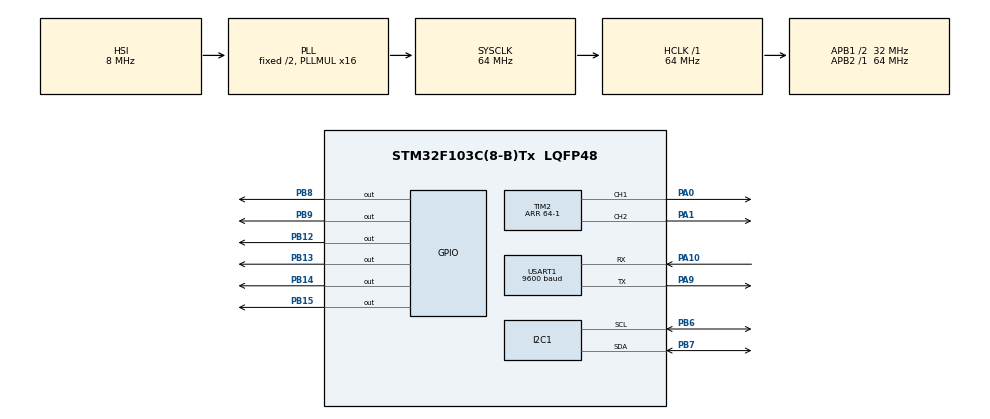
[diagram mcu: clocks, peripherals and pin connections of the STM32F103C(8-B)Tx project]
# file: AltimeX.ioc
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Dma.Request0=TIM2_CH2/CH4
Dma.Request1=USART1_RX
Dma.TIM2_CH2/CH4.0.Direction=DMA_MEMORY_TO_PERIPH
Dma.TIM2_CH2/CH4.0.Instance=DMA1_Channel7
Dma.TIM2_CH2/CH4.0.MemDataAlignment=DMA_MDATAALIGN_HALFWORD
Dma.TIM2_CH2/CH4.0.MemInc=DMA_MINC_ENABLE
Dma.TIM2_CH2/CH4.0.Mode=DMA_NORMAL
Dma.TIM2_CH2/CH4.0.PeriphDataAlignment=DMA_PDATAALIGN_HALFWORD
Dma.TIM2_CH2/CH4.0.PeriphInc=DMA_PINC_DISABLE
Dma.TIM2_CH2/CH4.0.Priority=DMA_PRIORITY_LOW
Dma.USART1_RX.1.Direction=DMA_PERIPH_TO_MEMORY
Dma.USART1_RX.1.Instance=DMA1_Channel5
Dma.USART1_RX.1.MemDataAlignment=DMA_MDATAALIGN_BYTE
Dma.USART1_RX.1.MemInc=DMA_MINC_ENABLE
Dma.USART1_RX.1.Mode=DMA_CIRCULAR
Dma.USART1_RX.1.PeriphDataAlignment=DMA_PDATAALIGN_BYTE
Dma.USART1_RX.1.PeriphInc=DMA_PINC_DISABLE
Dma.USART1_RX.1.Priority=DMA_PRIORITY_LOW
I2C1.I2C_Mode=I2C_Standard
Mcu.Family=STM32F1
Mcu.Name=STM32F103C(8-B)Tx
Mcu.Package=LQFP48
NVIC.DMA1_Channel5_IRQn=true\:0\:0\:false\:false\:true\:false\:true\:true
NVIC.DMA1_Channel7_IRQn=true\:0\:0\:false\:false\:true\:false\:true\:true
NVIC.PriorityGroup=NVIC_PRIORITYGROUP_4
NVIC.USART1_IRQn=true\:0\:0\:false\:false\:true\:true\:true\:true
PA0-WKUP.Signal=S_TIM2_CH1_ETR
PA1.Signal=S_TIM2_CH2
PA10.Mode=Asynchronous
PA10.Signal=USART1_RX
PA9.Mode=Asynchronous
PA9.Signal=USART1_TX
PB12.Signal=GPIO_Output
PB13.Signal=GPIO_Output
PB14.Signal=GPIO_Output
PB15.Signal=GPIO_Output
PB6.Mode=I2C
PB6.Signal=I2C1_SCL
PB7.Mode=I2C
PB7.Signal=I2C1_SDA
PB8.Signal=GPIO_Output
PB9.Signal=GPIO_Output
ProjectManager.HeapSize=0x200
ProjectManager.StackSize=0x400
ProjectManager.TargetToolchain=STM32CubeIDE
RCC.ADCPresc=RCC_ADCPCLK2_DIV6
RCC.AHBFreq_Value=64000000
RCC.APB1CLKDivider=RCC_HCLK_DIV2
RCC.APB1Freq_Value=32000000
RCC.APB1TimFreq_Value=64000000
RCC.APB2Freq_Value=64000000
RCC.APB2TimFreq_Value=64000000
RCC.HCLKFreq_Value=64000000
RCC.PLLMUL=RCC_PLL_MUL16
RCC.SYSCLKFreq_VALUE=64000000
RCC.SYSCLKSource=RCC_SYSCLKSOURCE_PLLCLK
RCC.USBFreq_Value=64000000
SH.S_TIM2_CH1_ETR.0=TIM2_CH1,PWM Generation1 CH1
SH.S_TIM2_CH2.0=TIM2_CH2,PWM Generation2 CH2
TIM1.Prescaler=4-1
TIM2.Channel-PWM\ Generation1\ CH1=TIM_CHANNEL_1
TIM2.Channel-PWM\ Generation2\ CH2=TIM_CHANNEL_2
TIM2.Period=64-1
USART1.BaudRate=9600
USART1.VirtualMode=VM_ASYNC
VP_TIM1_VS_ClockSourceINT.Mode=Internal
VP_TIM2_VS_ClockSourceINT.Mode=Internal
board=custom

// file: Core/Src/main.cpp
/* USER CODE BEGIN Header */
/**
  ******************************************************************************
  * @file           : main.c
  * @brief          : Main program body
  ******************************************************************************
  * @attention
  *
  * Copyright (c) 2023 STMicroelectronics.
  * All rights reserved.
  *
  * This software is licensed under terms that can be found in the LICENSE file
  * in the root directory of this software component.
  * If no LICENSE file comes with this software, it is provided AS-IS.
  *
  ******************************************************************************
  */
/* USER CODE END Header */
#include "main.h"

/* USER CODE BEGIN Includes */
#include "altimex.h"
/* USER CODE END Includes */

I2C_HandleTypeDef hi2c1;

TIM_HandleTypeDef htim1;
TIM_HandleTypeDef htim2;
DMA_HandleTypeDef hdma_tim2_ch2_ch4;

UART_HandleTypeDef huart1;
DMA_HandleTypeDef hdma_usart1_rx;

void SystemClock_Config(void);
static void MX_GPIO_Init(void);
static void MX_DMA_Init(void);
static void MX_I2C1_Init(void);
static void MX_TIM2_Init(void);
static void MX_TIM1_Init(void);
static void MX_USART1_UART_Init(void);

int main(void)
{

  /* MCU Configuration--------------------------------------------------------*/

  /* Reset of all peripherals, Initializes the Flash interface and the Systick. */
  HAL_Init();

  /* Configure the system clock */
  SystemClock_Config();

  /* Initialize all configured peripherals */
  MX_GPIO_Init();
  MX_DMA_Init();
  MX_I2C1_Init();
  MX_TIM2_Init();
  MX_TIM1_Init();
  MX_USART1_UART_Init();
  /* USER CODE BEGIN 2 */

  Altimex* altimex = new Altimex(&huart1, &hi2c1, &htim2, 10000);
  /* USER CODE END 2 */

  /* Infinite loop */
  /* USER CODE BEGIN WHILE */
  while (1)
  {
	  altimex->tick();
    /* USER CODE END WHILE */

  }
}

void SystemClock_Config(void)
{
  RCC_OscInitTypeDef RCC_OscInitStruct = {0};
  RCC_ClkInitTypeDef RCC_ClkInitStruct = {0};

  /** Initializes the RCC Oscillators according to the specified parameters
  * in the RCC_OscInitTypeDef structure.
  */
  RCC_OscInitStruct.OscillatorType = RCC_OSCILLATORTYPE_HSI;
  RCC_OscInitStruct.HSIState = RCC_HSI_ON;
  RCC_OscInitStruct.HSICalibrationValue = RCC_HSICALIBRATION_DEFAULT;
  RCC_OscInitStruct.PLL.PLLState = RCC_PLL_ON;
  RCC_OscInitStruct.PLL.PLLSource = RCC_PLLSOURCE_HSI_DIV2;
  RCC_OscInitStruct.PLL.PLLMUL = RCC_PLL_MUL16;
  if (HAL_RCC_OscConfig(&RCC_OscInitStruct) != HAL_OK)
  {
    Error_Handler();
  }

  /** Initializes the CPU, AHB and APB buses clocks
  */
  RCC_ClkInitStruct.ClockType = RCC_CLOCKTYPE_HCLK|RCC_CLOCKTYPE_SYSCLK
                              |RCC_CLOCKTYPE_PCLK1|RCC_CLOCKTYPE_PCLK2;
  RCC_ClkInitStruct.SYSCLKSource = RCC_SYSCLKSOURCE_PLLCLK;
  RCC_ClkInitStruct.AHBCLKDivider = RCC_SYSCLK_DIV1;
  RCC_ClkInitStruct.APB1CLKDivider = RCC_HCLK_DIV2;
  RCC_ClkInitStruct.APB2CLKDivider = RCC_HCLK_DIV1;

  if (HAL_RCC_ClockConfig(&RCC_ClkInitStruct, FLASH_LATENCY_2) != HAL_OK)
  {
    Error_Handler();
  }
}

static void MX_I2C1_Init(void)
{

  hi2c1.Instance = I2C1;
  hi2c1.Init.ClockSpeed = 100000;
  hi2c1.Init.DutyCycle = I2C_DUTYCYCLE_2;
  hi2c1.Init.OwnAddress1 = 0;
  hi2c1.Init.AddressingMode = I2C_ADDRESSINGMODE_7BIT;
  hi2c1.Init.DualAddressMode = I2C_DUALADDRESS_DISABLE;
  hi2c1.Init.OwnAddress2 = 0;
  hi2c1.Init.GeneralCallMode = I2C_GENERALCALL_DISABLE;
  hi2c1.Init.NoStretchMode = I2C_NOSTRETCH_DISABLE;
  if (HAL_I2C_Init(&hi2c1) != HAL_OK)
  {
    Error_Handler();
  }

}

static void MX_TIM1_Init(void)
{

  TIM_ClockConfigTypeDef sClockSourceConfig = {0};
  TIM_MasterConfigTypeDef sMasterConfig = {0};

  htim1.Instance = TIM1;
  htim1.Init.Prescaler = 4-1;
  htim1.Init.CounterMode = TIM_COUNTERMODE_UP;
  htim1.Init.Period = 65535;
  htim1.Init.ClockDivision = TIM_CLOCKDIVISION_DIV1;
  htim1.Init.RepetitionCounter = 0;
  htim1.Init.AutoReloadPreload = TIM_AUTORELOAD_PRELOAD_DISABLE;
  if (HAL_TIM_Base_Init(&htim1) != HAL_OK)
  {
    Error_Handler();
  }
  sClockSourceConfig.ClockSource = TIM_CLOCKSOURCE_INTERNAL;
  if (HAL_TIM_ConfigClockSource(&htim1, &sClockSourceConfig) != HAL_OK)
  {
    Error_Handler();
  }
  sMasterConfig.MasterOutputTrigger = TIM_TRGO_RESET;
  sMasterConfig.MasterSlaveMode = TIM_MASTERSLAVEMODE_DISABLE;
  if (HAL_TIMEx_MasterConfigSynchronization(&htim1, &sMasterConfig) != HAL_OK)
  {
    Error_Handler();
  }

}

static void MX_TIM2_Init(void)
{

  TIM_ClockConfigTypeDef sClockSourceConfig = {0};
  TIM_MasterConfigTypeDef sMasterConfig = {0};
  TIM_OC_InitTypeDef sConfigOC = {0};

  htim2.Instance = TIM2;
  htim2.Init.Prescaler = 0;
  htim2.Init.CounterMode = TIM_COUNTERMODE_UP;
  htim2.Init.Period = 64-1;
  htim2.Init.ClockDivision = TIM_CLOCKDIVISION_DIV1;
  htim2.Init.AutoReloadPreload = TIM_AUTORELOAD_PRELOAD_DISABLE;
  if (HAL_TIM_Base_Init(&htim2) != HAL_OK)
  {
    Error_Handler();
  }
  sClockSourceConfig.ClockSource = TIM_CLOCKSOURCE_INTERNAL;
  if (HAL_TIM_ConfigClockSource(&htim2, &sClockSourceConfig) != HAL_OK)
  {
    Error_Handler();
  }
  if (HAL_TIM_PWM_Init(&htim2) != HAL_OK)
  {
    Error_Handler();
  }
  sMasterConfig.MasterOutputTrigger = TIM_TRGO_RESET;
  sMasterConfig.MasterSlaveMode = TIM_MASTERSLAVEMODE_DISABLE;
  if (HAL_TIMEx_MasterConfigSynchronization(&htim2, &sMasterConfig) != HAL_OK)
  {
    Error_Handler();
  }
  sConfigOC.OCMode = TIM_OCMODE_PWM1;
  sConfigOC.Pulse = 0;
  sConfigOC.OCPolarity = TIM_OCPOLARITY_HIGH;
  sConfigOC.OCFastMode = TIM_OCFAST_DISABLE;
  if (HAL_TIM_PWM_ConfigChannel(&htim2, &sConfigOC, TIM_CHANNEL_1) != HAL_OK)
  {
    Error_Handler();
  }
  if (HAL_TIM_PWM_ConfigChannel(&htim2, &sConfigOC, TIM_CHANNEL_2) != HAL_OK)
  {
    Error_Handler();
  }
  HAL_TIM_MspPostInit(&htim2);

}

static void MX_USART1_UART_Init(void)
{

  huart1.Instance = USART1;
  huart1.Init.BaudRate = 9600;
  huart1.Init.WordLength = UART_WORDLENGTH_8B;
  huart1.Init.StopBits = UART_STOPBITS_1;
  huart1.Init.Parity = UART_PARITY_NONE;
  huart1.Init.Mode = UART_MODE_TX_RX;
  huart1.Init.HwFlowCtl = UART_HWCONTROL_NONE;
  huart1.Init.OverSampling = UART_OVERSAMPLING_16;
  if (HAL_UART_Init(&huart1) != HAL_OK)
  {
    Error_Handler();
  }

}

static void MX_DMA_Init(void)
{

  /* DMA controller clock enable */
  __HAL_RCC_DMA1_CLK_ENABLE();

  /* DMA interrupt init */
  /* DMA1_Channel5_IRQn interrupt configuration */
  HAL_NVIC_SetPriority(DMA1_Channel5_IRQn, 0, 0);
  HAL_NVIC_EnableIRQ(DMA1_Channel5_IRQn);
  /* DMA1_Channel7_IRQn interrupt configuration */
  HAL_NVIC_SetPriority(DMA1_Channel7_IRQn, 0, 0);
  HAL_NVIC_EnableIRQ(DMA1_Channel7_IRQn);

}

static void MX_GPIO_Init(void)
{
  GPIO_InitTypeDef GPIO_InitStruct = {0};

  /* GPIO Ports Clock Enable */
  __HAL_RCC_GPIOA_CLK_ENABLE();
  __HAL_RCC_GPIOB_CLK_ENABLE();

  /*Configure GPIO pin Output Level */
  HAL_GPIO_WritePin(GPIOB, GPIO_PIN_12|GPIO_PIN_13|GPIO_PIN_14|GPIO_PIN_15
                          |GPIO_PIN_8|GPIO_PIN_9, GPIO_PIN_RESET);

  /*Configure GPIO pins : PB12 PB13 PB14 PB15
                           PB8 PB9 */
  GPIO_InitStruct.Pin = GPIO_PIN_12|GPIO_PIN_13|GPIO_PIN_14|GPIO_PIN_15
                          |GPIO_PIN_8|GPIO_PIN_9;
  GPIO_InitStruct.Mode = GPIO_MODE_OUTPUT_PP;
  GPIO_InitStruct.Pull = GPIO_NOPULL;
  GPIO_InitStruct.Speed = GPIO_SPEED_FREQ_LOW;
  HAL_GPIO_Init(GPIOB, &GPIO_InitStruct);

}

void Error_Handler(void)
{
  __disable_irq();
  while (1)
  {
  }
}
